VERSION ""

NS_ :

BS_:

BU_: VCU SAS GREW

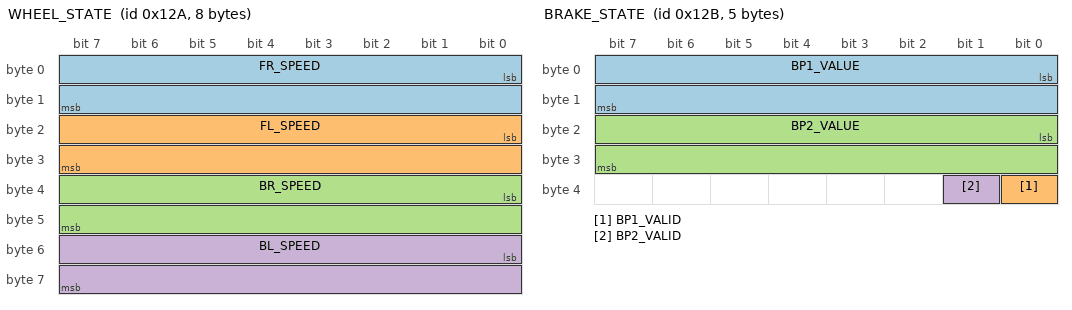
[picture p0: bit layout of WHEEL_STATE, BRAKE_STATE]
BO_ 298 WHEEL_STATE: 8 VCU
 SG_ FR_SPEED : 0|16@1- (0.01,0) [-100|100] "m/s" Vector__XXX
 SG_ FL_SPEED : 16|16@1- (0.01,0) [-100|100] "m/s" Vector__XXX
 SG_ BR_SPEED : 32|16@1- (0.01,0) [-100|100] "m/s" Vector__XXX
 SG_ BL_SPEED : 48|16@1- (0.01,0) [-100|100] "m/s" Vector__XXX

BO_ 299 BRAKE_STATE: 5 VCU
 SG_ BP1_VALUE : 0|16@1+ (0.1,0) [0|2000] "psi" Vector__XXX
 SG_ BP1_VALID : 32|1@1+ (1,0) [0|1] "" Vector__XXX
 SG_ BP2_VALUE : 16|16@1+ (0.1,0) [0|2000] "psi" Vector__XXX
 SG_ BP2_VALID : 33|1@1+ (1,0) [0|0] "" Vector__XXX

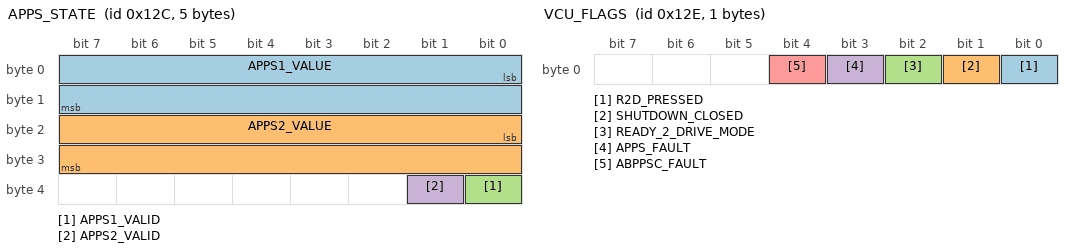
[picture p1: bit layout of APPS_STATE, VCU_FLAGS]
BO_ 300 APPS_STATE: 5 VCU
 SG_ APPS1_VALUE : 0|16@1+ (0.1,0) [0|100] "" Vector__XXX
 SG_ APPS2_VALUE : 16|16@1+ (0.1,0) [0|100] "" Vector__XXX
 SG_ APPS1_VALID : 32|1@1+ (1,0) [0|1] "" Vector__XXX
 SG_ APPS2_VALID : 33|1@1+ (1,0) [0|1] "" Vector__XXX

BO_ 302 VCU_FLAGS: 1 VCU
 SG_ R2D_PRESSED : 0|1@1+ (1,0) [0|1] "" Vector__XXX
 SG_ SHUTDOWN_CLOSED : 1|1@1+ (1,0) [0|1] "" Vector__XXX
 SG_ READY_2_DRIVE_MODE : 2|1@1+ (1,0) [0|1] "" Vector__XXX
 SG_ APPS_FAULT : 3|1@1+ (1,0) [0|0] "" Vector__XXX
 SG_ ABPPSC_FAULT : 4|1@1+ (1,0) [0|0] "" Vector__XXX

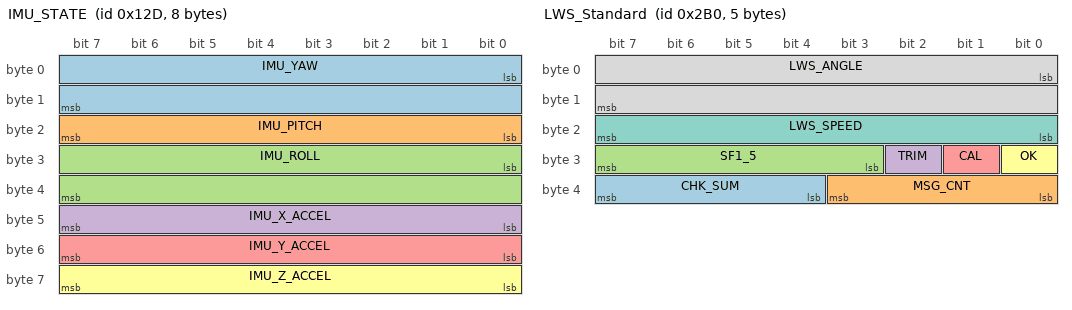
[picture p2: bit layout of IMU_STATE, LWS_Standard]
BO_ 301 IMU_STATE: 8 VCU
 SG_ IMU_YAW : 0|16@1- (1,0) [-180|180] "degrees" Vector__XXX
 SG_ IMU_PITCH : 16|8@1- (1,0) [-90|90] "degrees" Vector__XXX
 SG_ IMU_ROLL : 24|16@1- (1,0) [-180|180] "degrees" Vector__XXX
 SG_ IMU_X_ACCEL : 40|8@1- (0.1,0) [-12.8|12.7] "g" Vector__XXX
 SG_ IMU_Y_ACCEL : 48|8@1- (0.1,0) [-12.8|12.7] "g" Vector__XXX
 SG_ IMU_Z_ACCEL : 56|8@1- (0.1,0) [-12.8|12.7] "g" Vector__XXX

BO_ 1984 Message_LWS_CONFIG: 2 SAS
 SG_ RES : 4|12@1+ (1,0) [0|4095] "" Vector__XXX
 SG_ CCW : 0|4@1+ (1,0) [0|15] "" Vector__XXX

BO_ 688 LWS_Standard: 5 SAS
 SG_ CHK_SUM : 36|4@1+ (1,0) [0|15] "" Vector__XXX
 SG_ MSG_CNT : 32|4@1+ (1,0) [0|15] "" Vector__XXX
 SG_ SF1_5 : 27|5@1+ (1,0) [0|31] "" Vector__XXX
 SG_ TRIM : 26|1@1+ (1,0) [0|1] "" Vector__XXX
 SG_ CAL : 25|1@1+ (1,0) [0|1] "" Vector__XXX
 SG_ OK : 24|1@1+ (1,0) [0|1] "" Vector__XXX
 SG_ LWS_SPEED : 16|8@1+ (4,0) [0|1016] "°/s" Vector__XXX
 SG_ LWS_ANGLE : 0|16@1- (0.1,0) [-780|780] "°" Vector__XXX

BO_ 500 LOCK_CONFIG: 1 VCU
 SG_ LOCK_CONFIG : 0|1@1+ (1,0) [0|0] "bit" Vector__XXX

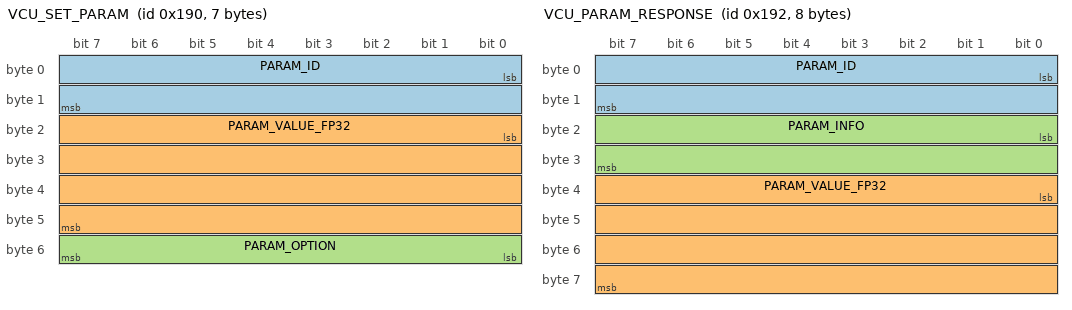
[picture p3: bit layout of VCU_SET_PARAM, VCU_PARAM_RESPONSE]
BO_ 400 VCU_SET_PARAM: 7 GREW
 SG_ PARAM_ID : 0|16@1+ (1,0) [0|0] "" Vector__XXX
 SG_ PARAM_VALUE_FP32 : 16|32@1+ (1E-06,0) [0|0] "" Vector__XXX
 SG_ PARAM_OPTION : 48|8@1+ (1,0) [0|0] "" Vector__XXX

BO_ 402 VCU_PARAM_RESPONSE: 8 VCU
 SG_ PARAM_ID : 0|16@1+ (1,0) [0|0] "" Vector__XXX
 SG_ PARAM_VALUE_FP32 : 32|32@1+ (1E-06,0) [0|0] "" Vector__XXX
 SG_ PARAM_INFO : 16|16@1+ (1,0) [0|0] "" Vector__XXX

BO_ 3221225472 VECTOR__INDEPENDENT_SIG_MSG: 0 Vector__XXX
 SG_ PARAM_ID_2 : 8|8@1+ (1,0) [0|0] "" Vector__XXX
 SG_ CKSUM : 56|8@1+ (1,0) [0|0] "" Vector__XXX
 SG_ DATA_3 : 40|8@1+ (1,0) [0|0] "" Vector__XXX
 SG_ DATA_2 : 32|8@1+ (1,0) [0|0] "" Vector__XXX
 SG_ DATA_1 : 24|8@1+ (1,0) [0|0] "" Vector__XXX
 SG_ PARAM_ID : 0|16@1+ (1,0) [0|0] "" Vector__XXX
 SG_ PARAM_OPTION : 48|8@1+ (1,0) [0|0] "" Vector__XXX

BO_ 403 VCU_FLASH_MODE: 1 GREW
 SG_ FLASH_ENABLED : 0|1@1+ (1,0) [0|0] "bit" Vector__XXX

BO_ 404 VCU_FLASH_CONFIG: 0 GREW

CM_ SG_ 302 R2D_PRESSED "1 = pressed 0 = not pressed";
CM_ SG_ 302 SHUTDOWN_CLOSED "1 = closed 0 = open";
CM_ SG_ 302 READY_2_DRIVE_MODE "1 = ready
0 = idle";
CM_ SG_ 302 APPS_FAULT "apps sensor fault";
CM_ SG_ 302 ABPPSC_FAULT "apps and brake concurrently activated";
CM_ SG_ 403 FLASH_ENABLED "1 = on, 0 = off
";
